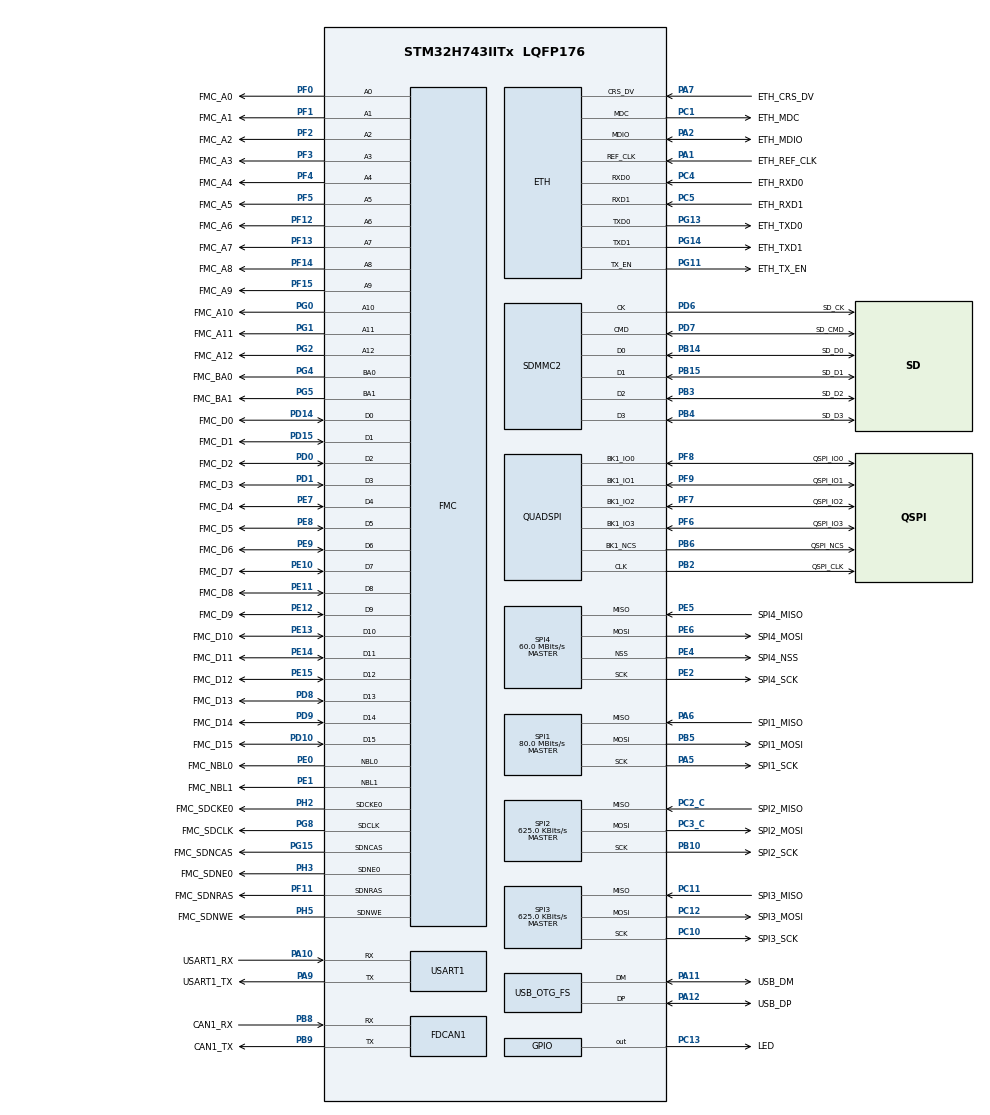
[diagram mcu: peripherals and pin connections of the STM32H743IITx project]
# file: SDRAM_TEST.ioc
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CORTEX_M7.AccessPermission_S-Cortex_Memory_Protection_Unit_Region1_Settings_S=MPU_REGION_FULL_ACCESS
CORTEX_M7.AccessPermission_Spec=MPU_REGION_FULL_ACCESS
CORTEX_M7.BaseAddress_S-Cortex_Memory_Protection_Unit_Region1_Settings_S=QSPI_BASE_INT
CORTEX_M7.BaseAddress_Spec=SDRAM_BASE
CORTEX_M7.CPU_DCache=Enabled
CORTEX_M7.CPU_ICache=Enabled
CORTEX_M7.DisableExec_S-Cortex_Memory_Protection_Unit_Region1_Settings_S=MPU_INSTRUCTION_ACCESS_DISABLE
CORTEX_M7.Enable_S-Cortex_Memory_Protection_Unit_Region1_Settings_S=MPU_REGION_ENABLE
CORTEX_M7.IsBufferable_S-Cortex_Memory_Protection_Unit_Region1_Settings_S=MPU_ACCESS_BUFFERABLE
CORTEX_M7.IsCacheable_S-Cortex_Memory_Protection_Unit_Region1_Settings_S=MPU_ACCESS_CACHEABLE
CORTEX_M7.IsCacheable_Spec=MPU_ACCESS_CACHEABLE
CORTEX_M7.IsShareable_S-Cortex_Memory_Protection_Unit_Region1_Settings_S=MPU_ACCESS_SHAREABLE
CORTEX_M7.IsShareable_Spec=MPU_ACCESS_NOT_SHAREABLE
CORTEX_M7.Size_S-Cortex_Memory_Protection_Unit_Region1_Settings_S=MPU_REGION_SIZE_128MB
CORTEX_M7.Size_Spec=MPU_REGION_SIZE_32MB
CORTEX_M7.SubRegionDisable_S-Cortex_Memory_Protection_Unit_Region1_Settings_S=0x00
CORTEX_M7.SubRegionDisable_Spec=0x00
CORTEX_M7.TypeExtField_S-Cortex_Memory_Protection_Unit_Region1_Settings_S=MPU_TEX_LEVEL1
CORTEX_M7.default_mode_Activation=1
Cesanta.I-CUBE-Mongoose.7.13.0.MG_ENABLE_PACKED_FS=false
ETH.MediaInterface=HAL_ETH_RMII_MODE
FDCAN1.CalculateBaudRateNominal=1250000
FDCAN1.CalculateTimeBitNominal=800
FDCAN1.CalculateTimeQuantumNominal=50.0
FDCAN1.NominalPrescaler=6
FDCAN1.NominalTimeSeg1=8
FDCAN1.NominalTimeSeg2=7
FMC.CASLatency1=FMC_SDRAM_CAS_LATENCY_3
FMC.ColumnBitsNumber1=FMC_SDRAM_COLUMN_BITS_NUM_9
FMC.ExitSelfRefreshDelay1=7
FMC.LoadToActiveDelay1=2
FMC.RCDDelay1=2
FMC.RPDelay1=2
FMC.RPDelay2=2
FMC.ReadPipeDelay1=FMC_SDRAM_RPIPE_DELAY_1
FMC.ReadPipeDelay2=FMC_SDRAM_RPIPE_DELAY_1
FMC.RowCycleDelay1=7
FMC.RowCycleDelay2=7
FMC.SDClockPeriod1=FMC_SDRAM_CLOCK_PERIOD_2
FMC.SDClockPeriod2=FMC_SDRAM_CLOCK_PERIOD_2
FMC.SelfRefreshTime1=4
FMC.WriteRecoveryTime1=3
Mcu.Family=STM32H7
Mcu.Name=STM32H743IITx
Mcu.Package=LQFP176
Mcu.UserConstants=SDRAM_BASE,0xC0000000;QSPI_BASE_INT,0x90000000
NVIC.FMC_IRQn=true\:0\:0\:false\:false\:true\:true\:true\:true
NVIC.PriorityGroup=NVIC_PRIORITYGROUP_4
NVIC.QUADSPI_IRQn=true\:0\:0\:false\:false\:true\:true\:true\:true
NVIC.USART1_IRQn=true\:0\:0\:false\:false\:true\:true\:true\:true
PA1.GPIO_Label=ETH_REF_CLK
PA1.GPIO_Speed=GPIO_SPEED_FREQ_VERY_HIGH
PA1.Mode=RMII
PA1.Signal=ETH_REF_CLK
PA10.GPIO_Label=USART1_RX
PA10.GPIO_Speed=GPIO_SPEED_FREQ_VERY_HIGH
PA10.Mode=Asynchronous
PA10.Signal=USART1_RX
PA11.GPIO_Label=USB_DM
PA11.GPIO_Speed=GPIO_SPEED_FREQ_VERY_HIGH
PA11.Mode=Device_Only
PA11.Signal=USB_OTG_FS_DM
PA12.GPIO_Label=USB_DP
PA12.GPIO_Speed=GPIO_SPEED_FREQ_VERY_HIGH
PA12.Mode=Device_Only
PA12.Signal=USB_OTG_FS_DP
PA13\ (JTMS/SWDIO).GPIO_Label=SWDIO
PA13\ (JTMS/SWDIO).Mode=Serial_Wire
PA13\ (JTMS/SWDIO).Signal=DEBUG_JTMS-SWDIO
PA14\ (JTCK/SWCLK).GPIO_Label=SWCLK
PA14\ (JTCK/SWCLK).Mode=Serial_Wire
PA14\ (JTCK/SWCLK).Signal=DEBUG_JTCK-SWCLK
PA2.GPIO_Label=ETH_MDIO
PA2.GPIO_Speed=GPIO_SPEED_FREQ_VERY_HIGH
PA2.Mode=RMII
PA2.Signal=ETH_MDIO
PA5.GPIO_Label=SPI1_SCK
PA5.GPIO_Speed=GPIO_SPEED_FREQ_VERY_HIGH
PA5.Mode=Full_Duplex_Master
PA5.Signal=SPI1_SCK
PA6.GPIO_Label=SPI1_MISO
PA6.GPIO_Speed=GPIO_SPEED_FREQ_VERY_HIGH
PA6.Mode=Full_Duplex_Master
PA6.Signal=SPI1_MISO
PA7.GPIO_Label=ETH_CRS_DV
PA7.GPIO_Speed=GPIO_SPEED_FREQ_VERY_HIGH
PA7.Mode=RMII
PA7.Signal=ETH_CRS_DV
PA9.GPIO_Label=USART1_TX
PA9.GPIO_Speed=GPIO_SPEED_FREQ_VERY_HIGH
PA9.Mode=Asynchronous
PA9.Signal=USART1_TX
PB10.GPIO_Label=SPI2_SCK
PB10.GPIO_Speed=GPIO_SPEED_FREQ_VERY_HIGH
PB10.Mode=Full_Duplex_Master
PB10.Signal=SPI2_SCK
PB14.GPIO_Label=SD_D0
PB14.Mode=SD_4_bits_Wide_bus
PB14.Signal=SDMMC2_D0
PB15.GPIO_Label=SD_D1
PB15.Mode=SD_4_bits_Wide_bus
PB15.Signal=SDMMC2_D1
PB2.GPIO_Label=QSPI_CLK
PB2.GPIO_Speed=GPIO_SPEED_FREQ_VERY_HIGH
PB2.Mode=Single Bank 1
PB2.Signal=QUADSPI_CLK
PB3\ (JTDO/TRACESWO).GPIO_Label=SD_D2
PB3\ (JTDO/TRACESWO).Mode=SD_4_bits_Wide_bus
PB3\ (JTDO/TRACESWO).Signal=SDMMC2_D2
PB4\ (NJTRST).GPIO_Label=SD_D3
PB4\ (NJTRST).Mode=SD_4_bits_Wide_bus
PB4\ (NJTRST).Signal=SDMMC2_D3
PB5.GPIO_Label=SPI1_MOSI
PB5.GPIO_Speed=GPIO_SPEED_FREQ_VERY_HIGH
PB5.Mode=Full_Duplex_Master
PB5.Signal=SPI1_MOSI
PB6.GPIO_FM6=SYSCFG_PMCR_I2C_PB6_FMP
PB6.GPIO_Label=QSPI_NCS
PB6.GPIO_Speed=GPIO_SPEED_FREQ_VERY_HIGH
PB6.Mode=Single Bank 1
PB6.Signal=QUADSPI_BK1_NCS
PB8.GPIO_FM8=SYSCFG_PMCR_I2C_PB8_FMP
PB8.GPIO_Label=CAN1_RX
PB8.GPIO_Speed=GPIO_SPEED_FREQ_VERY_HIGH
PB8.Mode=FDCAN_Activate
PB8.Signal=FDCAN1_RX
PB9.GPIO_FM9=SYSCFG_PMCR_I2C_PB9_FMP
PB9.GPIO_Label=CAN1_TX
PB9.GPIO_Speed=GPIO_SPEED_FREQ_VERY_HIGH
PB9.Mode=FDCAN_Activate
PB9.Signal=FDCAN1_TX
PC1.GPIO_Label=ETH_MDC
PC1.GPIO_Speed=GPIO_SPEED_FREQ_VERY_HIGH
PC1.Mode=RMII
PC1.Signal=ETH_MDC
PC10.GPIO_Label=SPI3_SCK
PC10.GPIO_Speed=GPIO_SPEED_FREQ_VERY_HIGH
PC10.Mode=Full_Duplex_Master
PC10.Signal=SPI3_SCK
PC11.GPIO_Label=SPI3_MISO
PC11.GPIO_Speed=GPIO_SPEED_FREQ_VERY_HIGH
PC11.Mode=Full_Duplex_Master
PC11.Signal=SPI3_MISO
PC12.GPIO_Label=SPI3_MOSI
PC12.GPIO_Speed=GPIO_SPEED_FREQ_VERY_HIGH
PC12.Mode=Full_Duplex_Master
PC12.Signal=SPI3_MOSI
PC13.GPIO_Label=LED
PC13.Signal=GPIO_Output
PC14-OSC32_IN\ (OSC32_IN).GPIO_Label=OSC32_IN
PC14-OSC32_IN\ (OSC32_IN).Mode=LSE-External-Oscillator
PC14-OSC32_IN\ (OSC32_IN).Signal=RCC_OSC32_IN
PC15-OSC32_OUT\ (OSC32_OUT).GPIO_Label=OSC32_OUT
PC15-OSC32_OUT\ (OSC32_OUT).Mode=LSE-External-Oscillator
PC15-OSC32_OUT\ (OSC32_OUT).Signal=RCC_OSC32_OUT
PC2_C.GPIO_Label=SPI2_MISO
PC2_C.GPIO_Speed=GPIO_SPEED_FREQ_VERY_HIGH
PC2_C.Mode=Full_Duplex_Master
PC2_C.Signal=SPI2_MISO
PC3_C.GPIO_Label=SPI2_MOSI
PC3_C.GPIO_Speed=GPIO_SPEED_FREQ_VERY_HIGH
PC3_C.Mode=Full_Duplex_Master
PC3_C.Signal=SPI2_MOSI
PC4.GPIO_Label=ETH_RXD0
PC4.GPIO_Speed=GPIO_SPEED_FREQ_VERY_HIGH
PC4.Mode=RMII
PC4.Signal=ETH_RXD0
PC5.GPIO_Label=ETH_RXD1
PC5.GPIO_Speed=GPIO_SPEED_FREQ_VERY_HIGH
PC5.Mode=RMII
PC5.Signal=ETH_RXD1
PD0.GPIO_Label=FMC_D2
PD0.Signal=FMC_D2_DA2
PD1.GPIO_Label=FMC_D3
PD1.Signal=FMC_D3_DA3
PD10.GPIO_Label=FMC_D15
PD10.Signal=FMC_D15_DA15
PD14.GPIO_Label=FMC_D0
PD14.Signal=FMC_D0_DA0
PD15.GPIO_Label=FMC_D1
PD15.Signal=FMC_D1_DA1
PD6.GPIO_Label=SD_CK
PD6.Mode=SD_4_bits_Wide_bus
PD6.Signal=SDMMC2_CK
PD7.GPIO_Label=SD_CMD
PD7.Mode=SD_4_bits_Wide_bus
PD7.Signal=SDMMC2_CMD
PD8.GPIO_Label=FMC_D13
PD8.Signal=FMC_D13_DA13
PD9.GPIO_Label=FMC_D14
PD9.Signal=FMC_D14_DA14
PE0.GPIO_Label=FMC_NBL0
PE0.Signal=FMC_NBL0
PE1.GPIO_Label=FMC_NBL1
PE1.Signal=FMC_NBL1
PE10.GPIO_Label=FMC_D7
PE10.Signal=FMC_D7_DA7
PE11.GPIO_Label=FMC_D8
PE11.Signal=FMC_D8_DA8
PE12.GPIO_Label=FMC_D9
PE12.Signal=FMC_D9_DA9
PE13.GPIO_Label=FMC_D10
PE13.Signal=FMC_D10_DA10
PE14.GPIO_Label=FMC_D11
PE14.Signal=FMC_D11_DA11
PE15.GPIO_Label=FMC_D12
PE15.Signal=FMC_D12_DA12
PE2.GPIO_Label=SPI4_SCK
PE2.GPIO_Speed=GPIO_SPEED_FREQ_VERY_HIGH
PE2.Mode=Full_Duplex_Master
PE2.Signal=SPI4_SCK
PE4.GPIO_Label=SPI4_NSS
PE4.GPIO_Speed=GPIO_SPEED_FREQ_VERY_HIGH
PE4.Mode=NSS_Signal_Hard_Output
PE4.Signal=SPI4_NSS
PE5.GPIO_Label=SPI4_MISO
PE5.GPIO_Speed=GPIO_SPEED_FREQ_VERY_HIGH
PE5.Mode=Full_Duplex_Master
PE5.Signal=SPI4_MISO
PE6.GPIO_Label=SPI4_MOSI
PE6.GPIO_Speed=GPIO_SPEED_FREQ_VERY_HIGH
PE6.Mode=Full_Duplex_Master
PE6.Signal=SPI4_MOSI
PE7.GPIO_Label=FMC_D4
PE7.Signal=FMC_D4_DA4
PE8.GPIO_Label=FMC_D5
PE8.Signal=FMC_D5_DA5
PE9.GPIO_Label=FMC_D6
PE9.Signal=FMC_D6_DA6
PF0.GPIO_Label=FMC_A0
PF0.Signal=FMC_A0
PF1.GPIO_Label=FMC_A1
PF1.Signal=FMC_A1
PF11.GPIO_Label=FMC_SDNRAS
PF11.Signal=FMC_SDNRAS
PF12.GPIO_Label=FMC_A6
PF12.Signal=FMC_A6
PF13.GPIO_Label=FMC_A7
PF13.Signal=FMC_A7
PF14.GPIO_Label=FMC_A8
PF14.Signal=FMC_A8
PF15.GPIO_Label=FMC_A9
PF15.Signal=FMC_A9
PF2.GPIO_Label=FMC_A2
PF2.Signal=FMC_A2
PF3.GPIO_Label=FMC_A3
PF3.Signal=FMC_A3
PF4.GPIO_Label=FMC_A4
PF4.Signal=FMC_A4
PF5.GPIO_Label=FMC_A5
PF5.Signal=FMC_A5
PF6.GPIO_Label=QSPI_IO3
PF6.GPIO_Speed=GPIO_SPEED_FREQ_VERY_HIGH
PF6.Mode=Single Bank 1
PF6.Signal=QUADSPI_BK1_IO3
PF7.GPIO_Label=QSPI_IO2
PF7.GPIO_Speed=GPIO_SPEED_FREQ_VERY_HIGH
PF7.Mode=Single Bank 1
PF7.Signal=QUADSPI_BK1_IO2
PF8.GPIO_Label=QSPI_IO0
PF8.GPIO_Speed=GPIO_SPEED_FREQ_VERY_HIGH
PF8.Mode=Single Bank 1
PF8.Signal=QUADSPI_BK1_IO0
PF9.GPIO_Label=QSPI_IO1
PF9.GPIO_Speed=GPIO_SPEED_FREQ_VERY_HIGH
PF9.Mode=Single Bank 1
PF9.Signal=QUADSPI_BK1_IO1
PG0.GPIO_Label=FMC_A10
PG0.Signal=FMC_A10
PG1.GPIO_Label=FMC_A11
PG1.Signal=FMC_A11
PG11.GPIO_Label=ETH_TX_EN
PG11.GPIO_Speed=GPIO_SPEED_FREQ_VERY_HIGH
PG11.Mode=RMII
PG11.Signal=ETH_TX_EN
PG13.GPIO_Label=ETH_TXD0
PG13.GPIO_Speed=GPIO_SPEED_FREQ_VERY_HIGH
PG13.Mode=RMII
PG13.Signal=ETH_TXD0
PG14.GPIO_Label=ETH_TXD1
PG14.GPIO_Speed=GPIO_SPEED_FREQ_VERY_HIGH
PG14.Mode=RMII
PG14.Signal=ETH_TXD1
PG15.GPIO_Label=FMC_SDNCAS
PG15.Signal=FMC_SDNCAS
PG2.GPIO_Label=FMC_A12
PG2.Signal=FMC_A12
PG4.GPIO_Label=FMC_BA0
PG4.Signal=FMC_A14_BA0
PG5.GPIO_Label=FMC_BA1
PG5.Signal=FMC_A15_BA1
PG8.GPIO_Label=FMC_SDCLK
PG8.Signal=FMC_SDCLK
PH0-OSC_IN\ (PH0).GPIO_Label=OSC_IN
PH0-OSC_IN\ (PH0).Mode=HSE-External-Oscillator
PH0-OSC_IN\ (PH0).Signal=RCC_OSC_IN
PH1-OSC_OUT\ (PH1).GPIO_Label=OSC_OUT
PH1-OSC_OUT\ (PH1).Mode=HSE-External-Oscillator
PH1-OSC_OUT\ (PH1).Signal=RCC_OSC_OUT
PH2.GPIO_Label=FMC_SDCKE0
PH2.Mode=SdramChipSelect1_1
PH2.Signal=FMC_SDCKE0
PH3.GPIO_Label=FMC_SDNE0
PH3.Mode=SdramChipSelect1_1
PH3.Signal=FMC_SDNE0
PH5.GPIO_Label=FMC_SDNWE
PH5.Signal=FMC_SDNWE
ProjectManager.HeapSize=0x0
ProjectManager.StackSize=0x400
ProjectManager.TargetToolchain=MDK-ARM V5.32
QUADSPI.ClockPrescaler=2
QUADSPI.FifoThreshold=4
QUADSPI.FlashSize=22
QUADSPI.SampleShifting=QSPI_SAMPLE_SHIFTING_HALFCYCLE
RCC.ADCFreq_Value=160000000
RCC.APB1Freq_Value=120000000
RCC.APB2Freq_Value=120000000
RCC.APB3Freq_Value=120000000
RCC.APB4Freq_Value=120000000
RCC.CortexFreq_Value=480000000
RCC.D1PPRE=RCC_APB3_DIV2
RCC.D2PPRE1=RCC_APB1_DIV2
RCC.D2PPRE2=RCC_APB2_DIV2
RCC.D3PPRE=RCC_APB4_DIV2
RCC.DIVM1=5
RCC.DIVM2=5
RCC.DIVM3=25
RCC.DIVN1=192
RCC.DIVN2=192
RCC.DIVN3=192
RCC.DIVP2=6
RCC.DIVQ1=8
RCC.DIVQ3=4
RCC.DIVR2=4
RCC.HCLKFreq_Value=240000000
RCC.HPRE=RCC_HCLK_DIV2
RCC.PLLSourceVirtual=RCC_PLLSOURCE_HSE
RCC.PWR_Regulator_Voltage_Scale=PWR_REGULATOR_VOLTAGE_SCALE0
RCC.ProductRev=revV
RCC.RNGCLockSelection=RCC_RNGCLKSOURCE_PLL
RCC.SDMMC1CLockSelection=RCC_SDMMCCLKSOURCE_PLL2
RCC.SPI123CLockSelection=RCC_SPI123CLKSOURCE_PLL2
RCC.SYSCLKFreq_VALUE=480000000
RCC.SYSCLKSource=RCC_SYSCLKSOURCE_PLLCLK
RCC.USBCLockSelection=RCC_USBCLKSOURCE_PLL3
RCC.USBFreq_Value=48000000
SH.FMC_A0.0=FMC_A0,13b-sda1
SH.FMC_A1.0=FMC_A1,13b-sda1
SH.FMC_A10.0=FMC_A10,13b-sda1
SH.FMC_A11.0=FMC_A11,13b-sda1
SH.FMC_A12.0=FMC_A12,13b-sda1
SH.FMC_A14_BA0.0=FMC_BA0,FourSdramBanks1
SH.FMC_A15_BA1.0=FMC_BA1,FourSdramBanks1
SH.FMC_A2.0=FMC_A2,13b-sda1
SH.FMC_A3.0=FMC_A3,13b-sda1
SH.FMC_A4.0=FMC_A4,13b-sda1
SH.FMC_A5.0=FMC_A5,13b-sda1
SH.FMC_A6.0=FMC_A6,13b-sda1
SH.FMC_A7.0=FMC_A7,13b-sda1
SH.FMC_A8.0=FMC_A8,13b-sda1
SH.FMC_A9.0=FMC_A9,13b-sda1
SH.FMC_D0_DA0.0=FMC_D0,sd-16b-d1
SH.FMC_D10_DA10.0=FMC_D10,sd-16b-d1
SH.FMC_D11_DA11.0=FMC_D11,sd-16b-d1
SH.FMC_D12_DA12.0=FMC_D12,sd-16b-d1
SH.FMC_D13_DA13.0=FMC_D13,sd-16b-d1
SH.FMC_D14_DA14.0=FMC_D14,sd-16b-d1
SH.FMC_D15_DA15.0=FMC_D15,sd-16b-d1
SH.FMC_D1_DA1.0=FMC_D1,sd-16b-d1
SH.FMC_D2_DA2.0=FMC_D2,sd-16b-d1
SH.FMC_D3_DA3.0=FMC_D3,sd-16b-d1
SH.FMC_D4_DA4.0=FMC_D4,sd-16b-d1
SH.FMC_D5_DA5.0=FMC_D5,sd-16b-d1
SH.FMC_D6_DA6.0=FMC_D6,sd-16b-d1
SH.FMC_D7_DA7.0=FMC_D7,sd-16b-d1
SH.FMC_D8_DA8.0=FMC_D8,sd-16b-d1
SH.FMC_D9_DA9.0=FMC_D9,sd-16b-d1
SH.FMC_NBL0.0=FMC_NBL0,Sd2ByteEnable1
SH.FMC_NBL1.0=FMC_NBL1,Sd2ByteEnable1
SH.FMC_SDCLK.0=FMC_SDCLK,13b-sda1
SH.FMC_SDNCAS.0=FMC_SDNCAS,13b-sda1
SH.FMC_SDNRAS.0=FMC_SDNRAS,13b-sda1
SH.FMC_SDNWE.0=FMC_SDNWE,13b-sda1
SPI1.CalculateBaudRate=80.0 MBits/s
SPI1.Direction=SPI_DIRECTION_2LINES
SPI1.Mode=SPI_MODE_MASTER
SPI1.VirtualType=VM_MASTER
SPI2.BaudRatePrescaler=SPI_BAUDRATEPRESCALER_256
SPI2.CalculateBaudRate=625.0 KBits/s
SPI2.Direction=SPI_DIRECTION_2LINES
SPI2.Mode=SPI_MODE_MASTER
SPI2.VirtualType=VM_MASTER
SPI3.BaudRatePrescaler=SPI_BAUDRATEPRESCALER_256
SPI3.CalculateBaudRate=625.0 KBits/s
SPI3.Direction=SPI_DIRECTION_2LINES
SPI3.Mode=SPI_MODE_MASTER
SPI3.VirtualType=VM_MASTER
SPI4.CalculateBaudRate=60.0 MBits/s
SPI4.Direction=SPI_DIRECTION_2LINES
SPI4.Mode=SPI_MODE_MASTER
SPI4.VirtualNSS=VM_NSSHARD
SPI4.VirtualType=VM_MASTER
USART1.VirtualMode-Asynchronous=VM_ASYNC
USB_OTG_FS.VirtualMode=Device_Only
VP_MEMORYMAP_VS_MEMORYMAP.Mode=CurAppReg
VP_RNG_VS_RNG.Mode=RNG_Activate
VP_emotas.I-CUBE-CANOPEN_VS_CANopenJjemotas_3.10.2_1.3.0.Mode=CANopenJjemotas
VP_emotas.I-CUBE-CANOPEN_VS_DeviceJjApplication_1.0.0_1.3.0.Mode=DeviceJjApplication
board=custom
emotas.I-CUBE-CANOPEN.1.3.0.CANopenJjemotas=true
emotas.I-CUBE-CANOPEN.1.3.0.DeviceJjApplication=Slave

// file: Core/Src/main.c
/* USER CODE BEGIN Header */
/**
  ******************************************************************************
  * @file           : main.c
  * @brief          : Main program body
  ******************************************************************************
  * @attention
  *
  * Copyright (c) 2023 STMicroelectronics.
  * All rights reserved.
  *
  * This software is licensed under terms that can be found in the LICENSE file
  * in the root directory of this software component.
  * If no LICENSE file comes with this software, it is provided AS-IS.
  *
  ******************************************************************************
  */
/* USER CODE END Header */
#include "main.h"
#include "eth.h"
#include "fdcan.h"
#include "memorymap.h"
#include "quadspi.h"
#include "rng.h"
#include "sdmmc.h"
#include "spi.h"
#include "usart.h"
#include "usb_otg.h"
#include "gpio.h"
#include "fmc.h"
#include "app_canopen.h"

/* USER CODE BEGIN Includes */
#include "bsp_sdram.h"

/* USER CODE END Includes */

void SystemClock_Config(void);
void PeriphCommonClock_Config(void);
static void MPU_Config(void);

/* USER CODE BEGIN 0 */

void mg_random(void *buf, size_t len)
{	// Use on-board RNG
	for (size_t n = 0; n < len; n += sizeof(uint32_t))
	{
		uint32_t r;
		HAL_RNG_GenerateRandomNumber(&hrng, &r);
		memcpy(
			(char *) buf + n,
			&r,
			n + sizeof(r) > len ? len - n : sizeof(r)
			);
	}
}

uint64_t mg_millis(void)
{
	return HAL_GetTick();
}

#if 0 // def __GNUC__
#define PUTCHAR_PROTOTYPE int __io_putchar(int ch)
#else
#define PUTCHAR_PROTOTYPE int fputc(int ch, FILE *f)
#endif

PUTCHAR_PROTOTYPE
{
	if (ch == '\n')
		putc('\r', f);
    HAL_UART_Transmit(&huart1 , (uint8_t *)&ch, 1, 0xFFFF);
    return ch;
}

ErrorCode_t ErrorCode = ERR_CODE_NONE;
uint32_t ErrorProcess = 0;

void ErrorFatal_Handler(void)
{
	__disable_irq();
	while (1)
	{
		HAL_GPIO_TogglePin(LED_GPIO_Port,LED_Pin);
		for(int j=0; j < 20; j++)
			for( int i = 0; i < 100000U; i++)
				__NOP();
	}
}

void LogInit(void)
{
	printf("\n\nSTM32H743II CAN " __DATE__ " " __TIME__ "\n");
}

typedef struct {
	const ErrorCode_t ErrorCode;
	const char *Message;
} ErrorMessage_t;

static const ErrorMessage_t ErrorMessages[] = {
	{ ERR_CODE_RNG, "RNG" },
	{ ERR_CODE_FMC, "FMC" },
	{ ERR_CODE_QSPI, "QSPI" },
	{ ERR_CODE_SDMMC, "SDMMC" },
	{ ERR_CODE_USB, "USB" },
	{ ERR_CODE_ETH, "ETH" },
	{ ERR_CODE_SPI1, "SPI1" },
	{ ERR_CODE_SPI2, "SPI2" },
	{ ERR_CODE_SPI3, "SPI3" },
	{ ERR_CODE_SPI4, "SPI4" },
	{ ERR_CODE_FDCAN, "FDCAN" },
	{ ERR_CODE_NONE, "OK" },
};

/* USER CODE END 0 */

int main(void)
{

  /* MPU Configuration--------------------------------------------------------*/
  MPU_Config();

  /* Enable the CPU Cache */

  /* Enable I-Cache---------------------------------------------------------*/
  SCB_EnableICache();

  /* Enable D-Cache---------------------------------------------------------*/
  SCB_EnableDCache();

  /* MCU Configuration--------------------------------------------------------*/

  /* Reset of all peripherals, Initializes the Flash interface and the Systick. */
  HAL_Init();

  /* Configure the system clock */
  SystemClock_Config();

  /* Configure the peripherals common clocks */
  PeriphCommonClock_Config();

  /* Initialize all configured peripherals */
  MX_GPIO_Init();
  MX_USART1_UART_Init();
  MX_RNG_Init();
  MX_FMC_Init();
  MX_QUADSPI_Init();
  MX_SDMMC2_SD_Init();
  MX_USB_OTG_FS_PCD_Init();
  MX_ETH_Init();
  MX_SPI1_Init();
  MX_SPI2_Init();
  MX_SPI3_Init();
  MX_SPI4_Init();
  MX_FDCAN1_Init();
  MX_CANopen_Init();
  /* USER CODE BEGIN 2 */

	// Simple SDRAM check
	for (int32_t i = 0; i < 100; i++)
	{
		*(uint8_t *)(SDRAM_BASE + i) = i + 100;
		*(uint16_t *)(SDRAM_BASE + 200 + i * 2) = i + 200;
	}
	for (int32_t i = 0; i < 100; i++)
	{
		if ((*(uint8_t *)(SDRAM_BASE + i) != i + 100) ||
			(*(uint16_t *)(SDRAM_BASE + 200 + i * 2) != i + 200)
			)
		{
			printf("addr:	%X	%d\n",SDRAM_BASE + i, *(uint8_t *)(SDRAM_BASE + i));
			printf("addr:	%X	%d\n",SDRAM_BASE + 200 + i * 2, *(uint8_t *)(SDRAM_BASE + 200 + i * 2));
		}
	}

  /* USER CODE END 2 */

  /* Infinite loop */
  /* USER CODE BEGIN WHILE */
	while (1)
	{
		HAL_GPIO_TogglePin(LED_GPIO_Port,LED_Pin);
		HAL_Delay(1000);
    /* USER CODE END WHILE */

	MX_CANopen_Process();
	}
}

void SystemClock_Config(void)
{
  RCC_OscInitTypeDef RCC_OscInitStruct = {0};
  RCC_ClkInitTypeDef RCC_ClkInitStruct = {0};

  /** Supply configuration update enable
  */
  HAL_PWREx_ConfigSupply(PWR_LDO_SUPPLY);

  /** Configure the main internal regulator output voltage
  */
  __HAL_PWR_VOLTAGESCALING_CONFIG(PWR_REGULATOR_VOLTAGE_SCALE0);

  while(!__HAL_PWR_GET_FLAG(PWR_FLAG_VOSRDY)) {}

  /** Initializes the RCC Oscillators according to the specified parameters
  * in the RCC_OscInitTypeDef structure.
  */
  RCC_OscInitStruct.OscillatorType = RCC_OSCILLATORTYPE_HSE;
  RCC_OscInitStruct.HSEState = RCC_HSE_ON;
  RCC_OscInitStruct.PLL.PLLState = RCC_PLL_ON;
  RCC_OscInitStruct.PLL.PLLSource = RCC_PLLSOURCE_HSE;
  RCC_OscInitStruct.PLL.PLLM = 5;
  RCC_OscInitStruct.PLL.PLLN = 192;
  RCC_OscInitStruct.PLL.PLLP = 2;
  RCC_OscInitStruct.PLL.PLLQ = 8;
  RCC_OscInitStruct.PLL.PLLR = 2;
  RCC_OscInitStruct.PLL.PLLRGE = RCC_PLL1VCIRANGE_2;
  RCC_OscInitStruct.PLL.PLLVCOSEL = RCC_PLL1VCOWIDE;
  RCC_OscInitStruct.PLL.PLLFRACN = 0;
  if (HAL_RCC_OscConfig(&RCC_OscInitStruct) != HAL_OK)
  {
    Error_Handler();
  }

  /** Initializes the CPU, AHB and APB buses clocks
  */
  RCC_ClkInitStruct.ClockType = RCC_CLOCKTYPE_HCLK|RCC_CLOCKTYPE_SYSCLK
                              |RCC_CLOCKTYPE_PCLK1|RCC_CLOCKTYPE_PCLK2
                              |RCC_CLOCKTYPE_D3PCLK1|RCC_CLOCKTYPE_D1PCLK1;
  RCC_ClkInitStruct.SYSCLKSource = RCC_SYSCLKSOURCE_PLLCLK;
  RCC_ClkInitStruct.SYSCLKDivider = RCC_SYSCLK_DIV1;
  RCC_ClkInitStruct.AHBCLKDivider = RCC_HCLK_DIV2;
  RCC_ClkInitStruct.APB3CLKDivider = RCC_APB3_DIV2;
  RCC_ClkInitStruct.APB1CLKDivider = RCC_APB1_DIV2;
  RCC_ClkInitStruct.APB2CLKDivider = RCC_APB2_DIV2;
  RCC_ClkInitStruct.APB4CLKDivider = RCC_APB4_DIV2;

  if (HAL_RCC_ClockConfig(&RCC_ClkInitStruct, FLASH_LATENCY_4) != HAL_OK)
  {
    Error_Handler();
  }
}

void PeriphCommonClock_Config(void)
{
  RCC_PeriphCLKInitTypeDef PeriphClkInitStruct = {0};

  /** Initializes the peripherals clock
  */
  PeriphClkInitStruct.PeriphClockSelection = RCC_PERIPHCLK_SDMMC|RCC_PERIPHCLK_SPI3
                              |RCC_PERIPHCLK_SPI2|RCC_PERIPHCLK_SPI1;
  PeriphClkInitStruct.PLL2.PLL2M = 5;
  PeriphClkInitStruct.PLL2.PLL2N = 192;
  PeriphClkInitStruct.PLL2.PLL2P = 6;
  PeriphClkInitStruct.PLL2.PLL2Q = 2;
  PeriphClkInitStruct.PLL2.PLL2R = 4;
  PeriphClkInitStruct.PLL2.PLL2RGE = RCC_PLL2VCIRANGE_2;
  PeriphClkInitStruct.PLL2.PLL2VCOSEL = RCC_PLL2VCOWIDE;
  PeriphClkInitStruct.PLL2.PLL2FRACN = 0;
  PeriphClkInitStruct.SdmmcClockSelection = RCC_SDMMCCLKSOURCE_PLL2;
  PeriphClkInitStruct.Spi123ClockSelection = RCC_SPI123CLKSOURCE_PLL2;
  if (HAL_RCCEx_PeriphCLKConfig(&PeriphClkInitStruct) != HAL_OK)
  {
    Error_Handler();
  }
}

 /* MPU Configuration */

void MPU_Config(void)
{
  MPU_Region_InitTypeDef MPU_InitStruct = {0};

  /* Disables the MPU */
  HAL_MPU_Disable();

  /** Initializes and configures the Region and the memory to be protected
  */
  MPU_InitStruct.Enable = MPU_REGION_ENABLE;
  MPU_InitStruct.Number = MPU_REGION_NUMBER0;
  MPU_InitStruct.BaseAddress = SDRAM_BASE;
  MPU_InitStruct.Size = MPU_REGION_SIZE_32MB;
  MPU_InitStruct.SubRegionDisable = 0x00;
  MPU_InitStruct.TypeExtField = MPU_TEX_LEVEL0;
  MPU_InitStruct.AccessPermission = MPU_REGION_FULL_ACCESS;
  MPU_InitStruct.DisableExec = MPU_INSTRUCTION_ACCESS_DISABLE;
  MPU_InitStruct.IsShareable = MPU_ACCESS_NOT_SHAREABLE;
  MPU_InitStruct.IsCacheable = MPU_ACCESS_CACHEABLE;
  MPU_InitStruct.IsBufferable = MPU_ACCESS_NOT_BUFFERABLE;

  HAL_MPU_ConfigRegion(&MPU_InitStruct);

  /** Initializes and configures the Region and the memory to be protected
  */
  MPU_InitStruct.Number = MPU_REGION_NUMBER1;
  MPU_InitStruct.BaseAddress = QSPI_BASE_INT;
  MPU_InitStruct.Size = MPU_REGION_SIZE_128MB;
  MPU_InitStruct.TypeExtField = MPU_TEX_LEVEL1;
  MPU_InitStruct.IsShareable = MPU_ACCESS_SHAREABLE;
  MPU_InitStruct.IsBufferable = MPU_ACCESS_BUFFERABLE;

  HAL_MPU_ConfigRegion(&MPU_InitStruct);
  /* Enables the MPU */
  HAL_MPU_Enable(MPU_PRIVILEGED_DEFAULT);

}

void Error_Handler(void)
{
  /* USER CODE BEGIN Error_Handler_Debug */
	if (ErrorCode == ERR_CODE_UART)
		ErrorFatal_Handler();
	const ErrorMessage_t *msg = &ErrorMessages[0];
	while (msg->ErrorCode != ERR_CODE_NONE)
	{
		if (msg->ErrorCode == ErrorCode)
		{
			printf("ERROR:%d %s\n", ErrorCode, msg->Message);
			return;
		}
		msg++;
	}
	printf("ERROR:%d\n", ErrorCode);
  /* USER CODE END Error_Handler_Debug */
}
